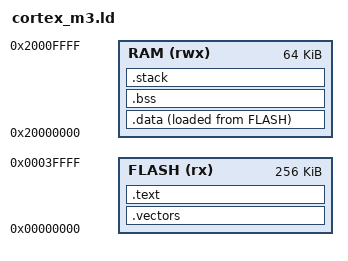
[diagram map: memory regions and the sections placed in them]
/* Linker script for QEMU LM3S6965 (Cortex-M3) */
MEMORY {
    FLASH (rx)  : ORIGIN = 0x00000000, LENGTH = 256K
    RAM   (rwx) : ORIGIN = 0x20000000, LENGTH = 64K
}

SECTIONS {
    .vectors : {
        KEEP(*(.vectors))
    } > FLASH

    .text : {
        *(.text*)
        *(.rodata*)
    } > FLASH

    .data : {
        *(.data*)
    } > RAM AT > FLASH

    .bss : {
        *(.bss*)
        *(COMMON)
    } > RAM

    .stack : {
        *(.stack)
    } > RAM

    /DISCARD/ : {
        *(.ARM.*)
        *(.comment)
    }
}
